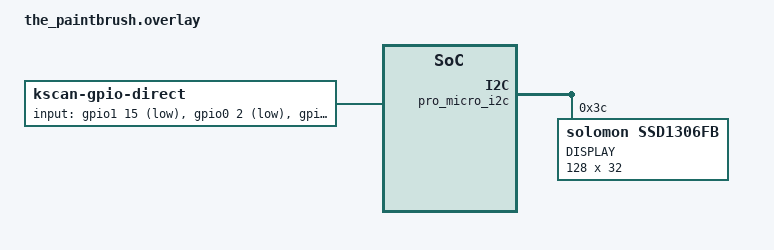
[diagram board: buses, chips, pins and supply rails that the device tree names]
/*
 * Copyright (c) 2021 Mike "KemoNine" Crosson
 *
 * SPDX-License-Identifier: MIT
 */

#include <dt-bindings/zmk/matrix_transform.h>

/ {
	chosen {
		zmk,kscan = &kscan0;
	};

	kscan0: kscan_0 {
		compatible = "zmk,kscan-gpio-direct";

		label = "KSCAN";

		input-gpios
			= <&gpio1 15 (GPIO_ACTIVE_LOW | GPIO_PULL_UP)>
			, <&gpio0 2  (GPIO_ACTIVE_LOW | GPIO_PULL_UP)>
			, <&gpio0 29 (GPIO_ACTIVE_LOW | GPIO_PULL_UP)>
			, <&gpio0 31 (GPIO_ACTIVE_LOW | GPIO_PULL_UP)>
			, <&gpio1 13 (GPIO_ACTIVE_LOW | GPIO_PULL_UP)>
			, <&gpio1 11 (GPIO_ACTIVE_LOW | GPIO_PULL_UP)>
			, <&gpio0 10 (GPIO_ACTIVE_LOW | GPIO_PULL_UP)>
			, <&gpio0 9  (GPIO_ACTIVE_LOW | GPIO_PULL_UP)>
			;

	};
};

&pro_micro_i2c {
	status = "okay";

	oled: ssd1306@3c {
		compatible = "solomon,ssd1306fb";
		reg = <0x3c>;
		label = "DISPLAY";
		width = <128>;
		height = <32>;
		segment-offset = <0>;
		page-offset = <0>;
		display-offset = <0>;
		multiplex-ratio = <31>;
		segment-remap;
		com-invdir;
		com-sequential;
		prechargep = <0x22>;
	};

};
